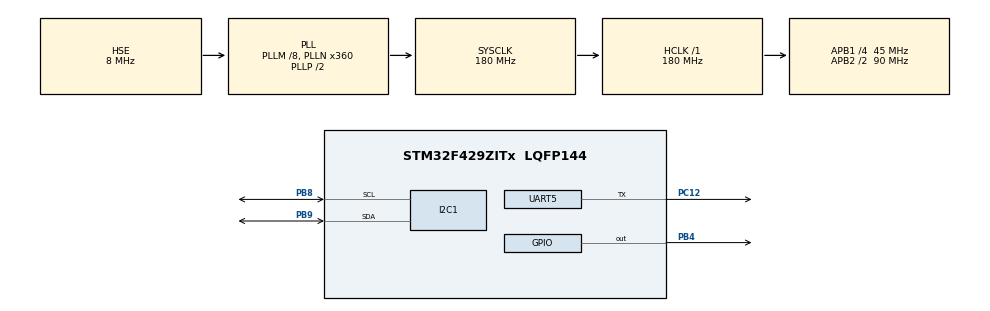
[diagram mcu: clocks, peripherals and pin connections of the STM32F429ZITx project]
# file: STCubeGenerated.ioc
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Mcu.Family=STM32F4
Dma.UART5_TX.1.PeriphInc=DMA_PINC_DISABLE
RCC.PLLSourceVirtual=RCC_PLLSOURCE_HSE
Dma.I2C1_RX.0.PeriphInc=DMA_PINC_DISABLE
RCC.CortexFreq_Value=180000000
Dma.I2C1_RX.0.MemDataAlignment=DMA_MDATAALIGN_BYTE
PC12.Signal=UART5_TX
UART5.VirtualMode=Asynchronous
RCC.APB1CLKDivider=RCC_HCLK_DIV4
RCC.SYSCLKSource=RCC_SYSCLKSOURCE_PLLCLK
ProjectManager.StackSize=0x4000
NVIC.UART5_IRQn=true\:0\:0\:false\:false\:true\:true\:true
PA13.Signal=SYS_JTMS-SWDIO
Dma.UART5_TX.1.PeriphDataAlignment=DMA_PDATAALIGN_BYTE
ProjectManager.TargetToolchain=MDK-ARM V5
Dma.UART5_TX.1.FIFOMode=DMA_FIFOMODE_DISABLE
I2C1.I2C_Mode=I2C_Fast
PH0/OSC_IN.Mode=HSE-External-Oscillator
RCC.HCLKFreq_Value=180000000
PB9.Mode=I2C
RCC.APB2TimFreq_Value=180000000
TIM3.Period=9999
Dma.I2C1_RX.0.MemInc=DMA_MINC_ENABLE
Dma.I2C1_RX.0.PeriphDataAlignment=DMA_PDATAALIGN_BYTE
PH1/OSC_OUT.Signal=RCC_OSC_OUT
Dma.UART5_TX.1.Direction=DMA_MEMORY_TO_PERIPH
TIM4.Prescaler=89
RCC.LSE_VALUE=32768
Dma.UART5_TX.1.MemDataAlignment=DMA_MDATAALIGN_BYTE
RCC.AHBFreq_Value=180000000
Dma.I2C1_RX.0.Priority=DMA_PRIORITY_LOW
Dma.UART5_TX.1.Instance=DMA1_Stream7
RCC.HSE_VALUE=8000000
PC12.Mode=Half_duplex(single_wire_mode)
board=custom
Dma.I2C1_RX.0.Mode=DMA_NORMAL
RCC.VCOOutputFreq_Value=360000000
NVIC.TIM3_IRQn=true\:1\:0\:true\:false\:true\:true\:true
PH0/OSC_IN.Signal=RCC_OSC_IN
RCC.APB2Freq_Value=90000000
PA14.Mode=Serial_Wire
TIM3.Prescaler=89
Dma.UART5_TX.1.Mode=DMA_NORMAL
Dma.I2C1_RX.0.Direction=DMA_PERIPH_TO_MEMORY
TIM4.Period=1599
UART5.Mode=MODE_TX
PA13.Mode=Serial_Wire
PH1/OSC_OUT.Mode=HSE-External-Oscillator
Mcu.Name=STM32F429ZITx
NVIC.DMA1_Stream7_IRQn=true\:0\:0\:false\:false\:true\:false\:true
RCC.48MHZClocksFreq_Value=90000000
RCC.SYSCLKFreq_VALUE=180000000
Mcu.Package=LQFP144
PB9.Signal=I2C1_SDA
Dma.UART5_TX.1.MemInc=DMA_MINC_ENABLE
PA14.Signal=SYS_JTCK-SWCLK
ProjectManager.HeapSize=0x2000
Dma.I2C1_RX.0.FIFOMode=DMA_FIFOMODE_DISABLE
PB9.GPIO_PuPdOD=GPIO_NOPULL
PB8.GPIO_PuPdOD=GPIO_NOPULL
RCC.HSI_VALUE=16000000
VP_TIM4_VS_ClockSourceINT.Mode=Internal
NVIC.PriorityGroup=NVIC_PRIORITYGROUP_4
RCC.APB2CLKDivider=RCC_HCLK_DIV2
RCC.PLLM=8
PB8.Mode=I2C
RCC.PLLN=360
Dma.Request1=UART5_TX
RCC.APB1TimFreq_Value=90000000
PB8.Signal=I2C1_SCL
NVIC.DMA1_Stream0_IRQn=true\:0\:0\:false\:false\:true\:false\:true
NVIC.TIM4_IRQn=true\:6\:0\:true\:false\:true\:true\:true
Dma.Request0=I2C1_RX
RCC.APB1Freq_Value=45000000
Dma.I2C1_RX.0.Instance=DMA1_Stream0
VP_TIM3_VS_ClockSourceINT.Mode=Internal
Dma.UART5_TX.1.Priority=DMA_PRIORITY_LOW
PB4.Signal=GPIO_Output

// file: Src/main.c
/* USER CODE BEGIN Header */
/**
  ******************************************************************************
  * @file           : main.c
  * @brief          : Main program body
  ******************************************************************************
  * @attention
  *
  * <h2><center>&copy; Copyright (c) 2020 STMicroelectronics.
  * All rights reserved.</center></h2>
  *
  * This software component is licensed by ST under BSD 3-Clause license,
  * the "License"; You may not use this file except in compliance with the
  * License. You may obtain a copy of the License at:
  *                        opensource.org/licenses/BSD-3-Clause
  *
  ******************************************************************************
  */
/* USER CODE END Header */
#include "main.h"

/* USER CODE BEGIN Includes */
#include "app_main.h"
#include "processing.h"

/* USER CODE END Includes */

I2C_HandleTypeDef hi2c1;
DMA_HandleTypeDef hdma_i2c1_rx;

TIM_HandleTypeDef htim3;
TIM_HandleTypeDef htim4;

UART_HandleTypeDef huart5;
DMA_HandleTypeDef hdma_uart5_tx;

/* USER CODE BEGIN PV */

uint8_t gsms_error = 0x00;

/* USER CODE END PV */

void SystemClock_Config(void);
static void MX_GPIO_Init(void);
static void MX_DMA_Init(void);
static void MX_I2C1_Init(void);
static void MX_TIM3_Init(void);
static void MX_TIM4_Init(void);
static void MX_UART5_Init(void);

int main(void)
{

  /* MCU Configuration--------------------------------------------------------*/

  /* Reset of all peripherals, Initializes the Flash interface and the Systick. */
  HAL_Init();

  /* Configure the system clock */
  SystemClock_Config();

  /* Initialize all configured peripherals */
  MX_GPIO_Init();
  MX_DMA_Init();
  MX_I2C1_Init();
  MX_TIM3_Init();
  MX_TIM4_Init();
  MX_UART5_Init();
  /* USER CODE BEGIN 2 */

  // initialize LEDs
  LED_init();

  // initialize app
  app_init();

  /* USER CODE END 2 */

  /* Infinite loop */
  /* USER CODE BEGIN WHILE */
  while (1)
  {
    // perform data processing
    processing();
    /* USER CODE END WHILE */

  }
}

void SystemClock_Config(void)
{
  RCC_OscInitTypeDef RCC_OscInitStruct = {0};
  RCC_ClkInitTypeDef RCC_ClkInitStruct = {0};

  /** Configure the main internal regulator output voltage
  */
  __HAL_RCC_PWR_CLK_ENABLE();
  __HAL_PWR_VOLTAGESCALING_CONFIG(PWR_REGULATOR_VOLTAGE_SCALE1);
  /** Initializes the RCC Oscillators according to the specified parameters
  * in the RCC_OscInitTypeDef structure.
  */
  RCC_OscInitStruct.OscillatorType = RCC_OSCILLATORTYPE_HSE;
  RCC_OscInitStruct.HSEState = RCC_HSE_ON;
  RCC_OscInitStruct.PLL.PLLState = RCC_PLL_ON;
  RCC_OscInitStruct.PLL.PLLSource = RCC_PLLSOURCE_HSE;
  RCC_OscInitStruct.PLL.PLLM = 8;
  RCC_OscInitStruct.PLL.PLLN = 360;
  RCC_OscInitStruct.PLL.PLLP = RCC_PLLP_DIV2;
  RCC_OscInitStruct.PLL.PLLQ = 4;
  if (HAL_RCC_OscConfig(&RCC_OscInitStruct) != HAL_OK)
  {
    Error_Handler();
  }
  /** Activate the Over-Drive mode
  */
  if (HAL_PWREx_EnableOverDrive() != HAL_OK)
  {
    Error_Handler();
  }
  /** Initializes the CPU, AHB and APB buses clocks
  */
  RCC_ClkInitStruct.ClockType = RCC_CLOCKTYPE_HCLK|RCC_CLOCKTYPE_SYSCLK
                              |RCC_CLOCKTYPE_PCLK1|RCC_CLOCKTYPE_PCLK2;
  RCC_ClkInitStruct.SYSCLKSource = RCC_SYSCLKSOURCE_PLLCLK;
  RCC_ClkInitStruct.AHBCLKDivider = RCC_SYSCLK_DIV1;
  RCC_ClkInitStruct.APB1CLKDivider = RCC_HCLK_DIV4;
  RCC_ClkInitStruct.APB2CLKDivider = RCC_HCLK_DIV2;

  if (HAL_RCC_ClockConfig(&RCC_ClkInitStruct, FLASH_LATENCY_5) != HAL_OK)
  {
    Error_Handler();
  }
}

static void MX_I2C1_Init(void)
{

  hi2c1.Instance = I2C1;
  hi2c1.Init.ClockSpeed = 400000;
  hi2c1.Init.DutyCycle = I2C_DUTYCYCLE_2;
  hi2c1.Init.OwnAddress1 = 0;
  hi2c1.Init.AddressingMode = I2C_ADDRESSINGMODE_7BIT;
  hi2c1.Init.DualAddressMode = I2C_DUALADDRESS_DISABLE;
  hi2c1.Init.OwnAddress2 = 0;
  hi2c1.Init.GeneralCallMode = I2C_GENERALCALL_DISABLE;
  hi2c1.Init.NoStretchMode = I2C_NOSTRETCH_DISABLE;
  if (HAL_I2C_Init(&hi2c1) != HAL_OK)
  {
    Error_Handler();
  }
  /** Configure Analogue filter
  */
  if (HAL_I2CEx_ConfigAnalogFilter(&hi2c1, I2C_ANALOGFILTER_ENABLE) != HAL_OK)
  {
    Error_Handler();
  }
  /** Configure Digital filter
  */
  if (HAL_I2CEx_ConfigDigitalFilter(&hi2c1, 0) != HAL_OK)
  {
    Error_Handler();
  }

}

static void MX_TIM3_Init(void)
{

  TIM_ClockConfigTypeDef sClockSourceConfig = {0};
  TIM_MasterConfigTypeDef sMasterConfig = {0};

  htim3.Instance = TIM3;
  htim3.Init.Prescaler = 89;
  htim3.Init.CounterMode = TIM_COUNTERMODE_UP;
  htim3.Init.Period = 9999;
  htim3.Init.ClockDivision = TIM_CLOCKDIVISION_DIV1;
  htim3.Init.AutoReloadPreload = TIM_AUTORELOAD_PRELOAD_DISABLE;
  if (HAL_TIM_Base_Init(&htim3) != HAL_OK)
  {
    Error_Handler();
  }
  sClockSourceConfig.ClockSource = TIM_CLOCKSOURCE_INTERNAL;
  if (HAL_TIM_ConfigClockSource(&htim3, &sClockSourceConfig) != HAL_OK)
  {
    Error_Handler();
  }
  sMasterConfig.MasterOutputTrigger = TIM_TRGO_RESET;
  sMasterConfig.MasterSlaveMode = TIM_MASTERSLAVEMODE_DISABLE;
  if (HAL_TIMEx_MasterConfigSynchronization(&htim3, &sMasterConfig) != HAL_OK)
  {
    Error_Handler();
  }

}

static void MX_TIM4_Init(void)
{

  TIM_ClockConfigTypeDef sClockSourceConfig = {0};
  TIM_MasterConfigTypeDef sMasterConfig = {0};

  htim4.Instance = TIM4;
  htim4.Init.Prescaler = 89;
  htim4.Init.CounterMode = TIM_COUNTERMODE_UP;
  htim4.Init.Period = 1599;
  htim4.Init.ClockDivision = TIM_CLOCKDIVISION_DIV1;
  htim4.Init.AutoReloadPreload = TIM_AUTORELOAD_PRELOAD_DISABLE;
  if (HAL_TIM_Base_Init(&htim4) != HAL_OK)
  {
    Error_Handler();
  }
  sClockSourceConfig.ClockSource = TIM_CLOCKSOURCE_INTERNAL;
  if (HAL_TIM_ConfigClockSource(&htim4, &sClockSourceConfig) != HAL_OK)
  {
    Error_Handler();
  }
  sMasterConfig.MasterOutputTrigger = TIM_TRGO_RESET;
  sMasterConfig.MasterSlaveMode = TIM_MASTERSLAVEMODE_DISABLE;
  if (HAL_TIMEx_MasterConfigSynchronization(&htim4, &sMasterConfig) != HAL_OK)
  {
    Error_Handler();
  }

}

static void MX_UART5_Init(void)
{

  huart5.Instance = UART5;
  huart5.Init.BaudRate = 115200;
  huart5.Init.WordLength = UART_WORDLENGTH_8B;
  huart5.Init.StopBits = UART_STOPBITS_1;
  huart5.Init.Parity = UART_PARITY_NONE;
  huart5.Init.Mode = UART_MODE_TX;
  huart5.Init.HwFlowCtl = UART_HWCONTROL_NONE;
  huart5.Init.OverSampling = UART_OVERSAMPLING_16;
  if (HAL_HalfDuplex_Init(&huart5) != HAL_OK)
  {
    Error_Handler();
  }

}

static void MX_DMA_Init(void)
{

  /* DMA controller clock enable */
  __HAL_RCC_DMA1_CLK_ENABLE();

  /* DMA interrupt init */
  /* DMA1_Stream0_IRQn interrupt configuration */
  HAL_NVIC_SetPriority(DMA1_Stream0_IRQn, 0, 0);
  HAL_NVIC_EnableIRQ(DMA1_Stream0_IRQn);
  /* DMA1_Stream7_IRQn interrupt configuration */
  HAL_NVIC_SetPriority(DMA1_Stream7_IRQn, 0, 0);
  HAL_NVIC_EnableIRQ(DMA1_Stream7_IRQn);

}

static void MX_GPIO_Init(void)
{
  GPIO_InitTypeDef GPIO_InitStruct = {0};

  /* GPIO Ports Clock Enable */
  __HAL_RCC_GPIOH_CLK_ENABLE();
  __HAL_RCC_GPIOA_CLK_ENABLE();
  __HAL_RCC_GPIOC_CLK_ENABLE();
  __HAL_RCC_GPIOB_CLK_ENABLE();

  /*Configure GPIO pin Output Level */
  HAL_GPIO_WritePin(GPIOB, GPIO_PIN_4, GPIO_PIN_RESET);

  /*Configure GPIO pin : PB4 */
  GPIO_InitStruct.Pin = GPIO_PIN_4;
  GPIO_InitStruct.Mode = GPIO_MODE_OUTPUT_PP;
  GPIO_InitStruct.Pull = GPIO_NOPULL;
  GPIO_InitStruct.Speed = GPIO_SPEED_FREQ_LOW;
  HAL_GPIO_Init(GPIOB, &GPIO_InitStruct);

}

void Error_Handler(void)
{
  /* USER CODE BEGIN Error_Handler_Debug */
  /* User can add his own implementation to report the HAL error return state */

  // turn on red LED
  HAL_GPIO_WritePin(GPIOB, GPIO_PIN_14, GPIO_PIN_SET);
  // loop forever
  while(1);

  /* USER CODE END Error_Handler_Debug */
}

/************************ (C) COPYRIGHT STMicroelectronics *****END OF FILE****/
